VERSION ""

NS_ :

BS_:

BU_: AAA BBB CM_SMK EEE FFF GGG KKK MMM NNN PPP SSS ZZZ

BO_ 256 FFF1: 8 FFF
 SG_ APS2 : 32|8@1+ (0.4,0) [0|100] "%" NNN
 SG_ VehicleAcceleration : 40|2@1+ (1,0) [0|3] "" NNN

BO_ 2179990510 EEE1: 8 EEE
 SG_ EPLACS : 16|8@1+ (1,0) [0|250] "%" MMM
 SG_ RAPP : 24|8@1+ (0.4,0) [0|100] "%" MMM

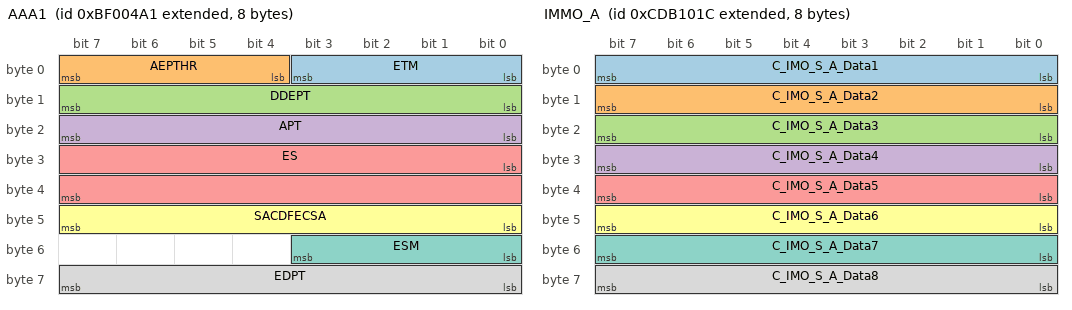
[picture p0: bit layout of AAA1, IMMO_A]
BO_ 2347762849 AAA1: 8 AAA
 SG_ ETM : 0|4@1+ (1,0) [0|15] "" KKK
 SG_ AEPTHR : 4|4@1+ (0.125,0) [0|0.875] "%" KKK
 SG_ DDEPT : 8|8@1+ (1,-125) [-125|125] "%" KKK
 SG_ APT : 16|8@1+ (1,-125) [-125|125] "%" KKK
 SG_ ES : 24|16@1+ (0.125,0) [0|8031.88] "rpm" KKK
 SG_ SACDFECSA : 40|8@1+ (1,0) [0|255] "" KKK
 SG_ ESM : 48|4@1+ (1,0) [0|15] "" KKK
 SG_ EDPT : 56|8@1+ (1,-125) [-125|125] "%" KKK

BO_ 2359362314 GGG1: 8 GGG
 SG_ MmntaryEngM : 42|2@1+ (1,0) [0|3] "" PPP
 SG_ DPFThermalM : 44|2@1+ (1,0) [0|3] "" PPP

BO_ 2363166748 IMMO_A: 8 CM_SMK
 SG_ C_IMO_S_A_Data1 : 0|8@1+ (1,0) [0|255] "" SSS
 SG_ C_IMO_S_A_Data2 : 8|8@1+ (1,0) [0|255] "" SSS
 SG_ C_IMO_S_A_Data3 : 16|8@1+ (1,0) [0|255] "" SSS
 SG_ C_IMO_S_A_Data4 : 24|8@1+ (1,0) [0|255] "" SSS
 SG_ C_IMO_S_A_Data5 : 32|8@1+ (1,0) [0|255] "" SSS
 SG_ C_IMO_S_A_Data6 : 40|8@1+ (1,0) [0|255] "" SSS
 SG_ C_IMO_S_A_Data7 : 48|8@1+ (1,0) [0|255] "" SSS
 SG_ C_IMO_S_A_Data8 : 56|8@1+ (1,0) [0|255] "" SSS

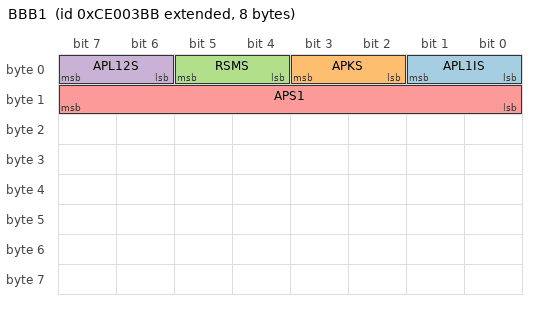
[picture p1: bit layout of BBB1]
BO_ 2363491259 BBB1: 8 BBB
 SG_ APL1IS : 0|2@1+ (1,0) [0|3] "" ZZZ
 SG_ APKS : 2|2@1+ (1,0) [0|3] "" ZZZ
 SG_ RSMS : 4|2@1+ (1,0) [0|3] "" ZZZ
 SG_ APL12S : 6|2@1+ (1,0) [0|3] "" ZZZ
 SG_ APS1 : 8|8@1+ (0.4,0) [0|100] "%" MMM

BA_DEF_ "BusType" STRING;
BA_DEF_ BU_ "NmStationAddress" HEX 0 255;
BA_DEF_ BO_ "VFrameFormat" ENUM "StandardCAN","ExtendedCAN","reserved","J1939PG","reserved","reserved","reserved","reserved","reserved","reserved","reserved","reserved","reserved","reserved","StandardCAN_FD","ExtendedCAN_FD";
BA_DEF_ BO_ "GenMsgCycleTime" INT 0 200000;
BA_DEF_ BO_ "GenMsgCycleTimeFast" INT 0 200000;
BA_DEF_ BO_ "GenMsgSendType" ENUM "Cyclic","NoMsgSendType";
BA_DEF_ BO_ "TpJ1939VarDlc" ENUM "No","Yes";
BA_DEF_ BO_ "GenMsgDelayTime" INT 0 1000;
BA_DEF_ BO_ "GenMsgRequestable" INT 0 1;
BA_DEF_ BO_ "GenMsgILSupport" ENUM "No","Yes";
BA_DEF_ SG_ "GenSigSendType" ENUM "NotUsed","OnWrite","OnWriteWithRepetition","OnChange","OnChangeWithRepetition","IfActive","IfActiveWithRepetition","NoSigSendType";
BA_DEF_ SG_ "GenSigStartValue" INT 0 100000;

BA_DEF_DEF_ "BusType" "CAN FD";
BA_DEF_DEF_ "NmStationAddress" 0;
BA_DEF_DEF_ "VFrameFormat" "StandardCAN_FD";
BA_DEF_DEF_ "GenMsgCycleTime" 0;
BA_DEF_DEF_ "GenMsgCycleTimeFast" 0;
BA_DEF_DEF_ "GenMsgSendType" "NoMsgSendType";
BA_DEF_DEF_ "TpJ1939VarDlc" "No";
BA_DEF_DEF_ "GenMsgDelayTime" 0;
BA_DEF_DEF_ "GenMsgRequestable" 0;
BA_DEF_DEF_ "GenMsgILSupport" "Yes";
BA_DEF_DEF_ "GenSigSendType" "NoSigSendType";
BA_DEF_DEF_ "GenSigStartValue" 0;

BA_ "NmStationAddress" BU_ AAA 234;
BA_ "NmStationAddress" BU_ BBB 235;
BA_ "NmStationAddress" BU_ EEE 239;
BA_ "NmStationAddress" BU_ FFF 238;
BA_ "NmStationAddress" BU_ GGG 239;
BA_ "NmStationAddress" BU_ CM_SMK 29;
BA_ "VFrameFormat" BO_ 2347762849 15;
BA_ "GenMsgCycleTime" BO_ 2347762849 10;
BA_ "GenMsgSendType" BO_ 2347762849 0;
BA_ "GenMsgRequestable" BO_ 2347762849 1;
BA_ "VFrameFormat" BO_ 2363491259 15;
BA_ "GenMsgCycleTime" BO_ 2363491259 50;
BA_ "GenMsgSendType" BO_ 2363491259 0;
BA_ "GenMsgRequestable" BO_ 2363491259 1;
BA_ "VFrameFormat" BO_ 2179990510 15;
BA_ "GenMsgSendType" BO_ 2179990510 0;
BA_ "GenMsgRequestable" BO_ 2179990510 1;
BA_ "GenMsgCycleTime" BO_ 256 50;
BA_ "GenMsgSendType" BO_ 256 0;
BA_ "GenMsgRequestable" BO_ 256 1;
BA_ "VFrameFormat" BO_ 2359362314 15;
BA_ "GenMsgSendType" BO_ 2359362314 0;
BA_ "GenMsgRequestable" BO_ 2359362314 1;
BA_ "VFrameFormat" BO_ 2363166748 15;
BA_ "GenMsgCycleTimeFast" BO_ 2363166748 40;
BA_ "GenMsgRequestable" BO_ 2363166748 1;
BA_ "GenSigSendType" SG_ 2363166748 C_IMO_S_A_Data1 2;
BA_ "GenSigSendType" SG_ 2363166748 C_IMO_S_A_Data2 2;
BA_ "GenSigSendType" SG_ 2363166748 C_IMO_S_A_Data3 2;
BA_ "GenSigSendType" SG_ 2363166748 C_IMO_S_A_Data4 2;
BA_ "GenSigSendType" SG_ 2363166748 C_IMO_S_A_Data5 2;
BA_ "GenSigSendType" SG_ 2363166748 C_IMO_S_A_Data6 2;
BA_ "GenSigSendType" SG_ 2363166748 C_IMO_S_A_Data7 2;
BA_ "GenSigSendType" SG_ 2363166748 C_IMO_S_A_Data8 2;
